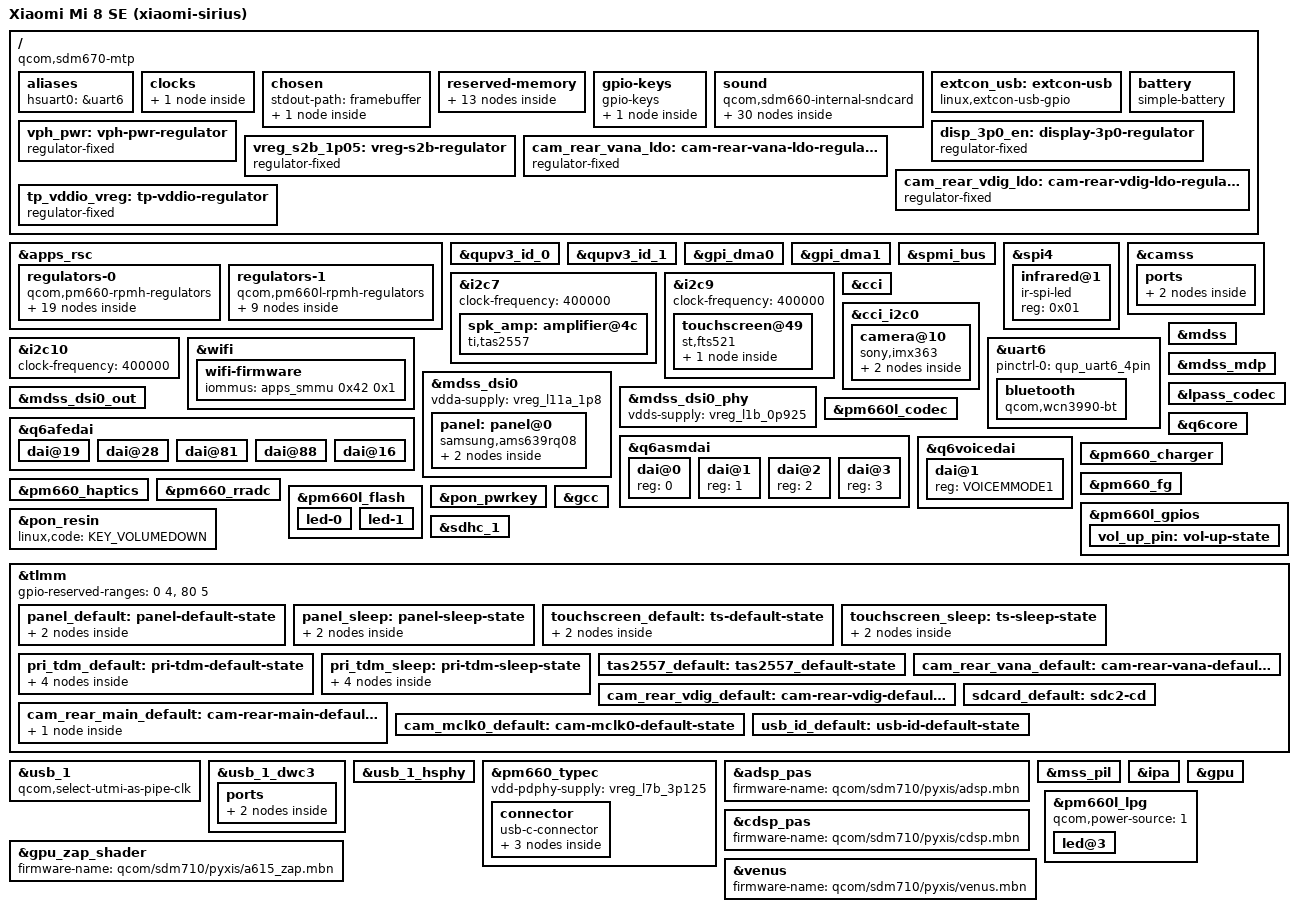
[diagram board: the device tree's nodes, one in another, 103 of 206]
// SPDX-License-Identifier: GPL-2.0
/*
 * Device tree for Xiaomi Mi 8 SE (xiaomi-sirius), based on
 * sdm670-google-sargo, downstream vendor kernel, and LineageOS DTS.
 *
 * Copyright (c) 2026, The Linux Foundation. All rights reserved.
*/

/dts-v1/;
#include <dt-bindings/firmware/qcom,scm.h>
#include <dt-bindings/gpio/gpio.h>
#include <dt-bindings/input/input.h>
#include <dt-bindings/leds/common.h>
#include <dt-bindings/pinctrl/qcom,pmic-gpio.h>
#include <dt-bindings/power/qcom-rpmpd.h>
#include <dt-bindings/sound/qcom,q6afe.h>
#include <dt-bindings/sound/qcom,q6asm.h>
#include <dt-bindings/sound/qcom,q6voice.h>
#include <dt-bindings/usb/pd.h>
#include "sdm710.dtsi"
#include "pm660.dtsi"
#include "pm660l.dtsi"

/delete-node/ &xbl_mem;
/delete-node/ &wlan_msa_mem;
/delete-node/ &cdsp_mem;
/delete-node/ &mba_region;
/delete-node/ &adsp_mem;
/delete-node/ &ipa_fw_mem;
/delete-node/ &ipa_gsi_mem;
/delete-node/ &gpu_mem;
/delete-node/ &rmtfs_mem;

/ {
	model = "Xiaomi Mi 8 SE (xiaomi-sirius)";
	compatible = "qcom,sdm670-mtp", "qcom,sdm670", "qcom,mtp";
	qcom,msm-id = <0x360 0 393 0>;
	qcom,board-id = <35 0>;
	chassis-type = "handset";

	aliases {
		hsuart0 = &uart6;
	};

	clocks {
		int_cdc_bclk: int-cdc-bclk {
			compatible = "fixed-clock";
			#clock-cells = <0>;
			clock-frequency = <1536000>;
		};
	};

	chosen {
		stdout-path = "framebuffer";
		#address-cells = <2>;
		#size-cells = <2>;
		ranges;

		framebuffer: framebuffer@9c000000 {
			compatible = "simple-framebuffer";
			reg = <0 0x9c000000 0 (1080 * 2240 * 4)>;
			width = <1080>;
			height = <2240>;
			stride = <(1080 * 4)>;
			format = "a8r8g8b8";
			status = "okay";
		};
	};

	reserved-memory {
		#address-cells = <2>;
		#size-cells = <2>;

		xbl_mem: memory@85e00000 {
			reg = <0 0x85e00000 0 0x1c0000>;
			no-map;
		};

		// 2026-10-15: old range 85fc0000-8ab00000 overlapped aop-mem + aop-cmd-db
		// (sdm670.dtsi, still no-map there) -> dmesg OVERLAP DETECTED. End kept 8ab00000.
		removed_region: removed-region {
			reg = <0 0x88f00000 0 0x1c00000>;
			no-map;
		};

		wlan_msa_mem: wlan-msa@93300000 {
			reg = <0 0x93300000 0 0x100000>;
			no-map;
		};

		cdsp_mem: cdsp@93400000 {
			reg = <0 0x93400000 0 0x800000>;
			no-map;
		};

		mba_region: mba@93c00000 {
			reg = <0 0x93c00000 0 0x200000>;
			no-map;
		};

		adsp_mem: adsp@93e00000 {
			reg = <0 0x93e00000 0 0x2200000>;
			no-map;
		};

		ipa_fw_mem: ipa-fw@97600000 {
			reg = <0 0x97600000 0 0x10000>;
			no-map;
		};

		ipa_gsi_mem: ipa-gsi@97610000 {
			reg = <0 0x97610000 0 0x5000>;
			no-map;
		};

		gpu_mem: gpu@97615000 {
			reg = <0 0x97615000 0 0x2000>;
			no-map;
		};

		fb_mem: framebuffer@9c000000 {
			reg = <0 0x9c000000 0 0x2300000>;
			no-map;
		};

		rmtfs_lower_guard: rmtfs-lower-guard@fc200000 {
			reg = <0 0xfc200000 0 0x1000>;
			no-map;
		};

		rmtfs_mem: rmtfs-mem@fc201000 {
			compatible = "qcom,rmtfs-mem";
			reg = <0 0xfc201000 0 0x200000>;
			no-map;
			qcom,client-id = <1>;
			qcom,vmid = <QCOM_SCM_VMID_MSS_MSA>;
		};

		rmtfs_upper_guard: rmtfs-upper-guard@fc401000 {
			reg = <0 0xfc401000 0 0x1000>;
			no-map;
		};
	};

	gpio-keys {
		compatible = "gpio-keys";
		autorepeat;

		pinctrl-names = "default";
		pinctrl-0 = <&vol_up_pin>;

		key-vol-up {
			label = "Volume Up";
			linux,code = <KEY_VOLUMEUP>;
			gpios = <&pm660l_gpios 7 GPIO_ACTIVE_LOW>;
		};
	};

	// AUDIO: WIP
	sound: sound {
		compatible = "qcom,sdm660-internal-sndcard";
		model = "Xiaomi Mi 8 SE";

		pinctrl-names = "default";
		/* cdc_pdm_default needs gpio18-20 (slimbus), taken by camera CCI on sirius; speaker/headset via TDM+tas2552 do not need it */
		pinctrl-0 = <&pri_tdm_default>;

		audio-routing = "Analog PDM_RX1", "Digital PDM_RX1",
			"Analog PDM_RX2", "Digital PDM_RX2",
			"Analog PDM_RX3", "Digital PDM_RX3",
			"Digital LPASS_PDM_TX", "Analog PDM_TX",
			"Analog AMIC1", "Analog MIC BIAS External1",
			"Analog AMIC2", "Analog MIC BIAS External2",
			"Analog AMIC3", "Analog MIC BIAS External1";

		mm1-dai-link {
			link-name = "MultiMedia1";

			cpu {
				sound-dai = <&q6asmdai MSM_FRONTEND_DAI_MULTIMEDIA1>;
			};
		};

		mm2-dai-link {
			link-name = "MultiMedia2";

			cpu {
				sound-dai = <&q6asmdai MSM_FRONTEND_DAI_MULTIMEDIA2>;
			};
		};

		mm3-dai-link {
			link-name = "MultiMedia3";

			cpu {
				sound-dai = <&q6asmdai MSM_FRONTEND_DAI_MULTIMEDIA3>;
			};
		};

		mm4-dai-link {
			link-name = "MultiMedia4";

			cpu {
				sound-dai = <&q6asmdai MSM_FRONTEND_DAI_MULTIMEDIA4>;
			};
		};

		voicemmode1-dai-link {
			link-name = "VoiceMMode1";

			cpu {
				sound-dai = <&q6voicedai VOICEMMODE1>;
			};
		};

		pri-tdm-tx-link {
			link-name = "Primary TDM0 Capture";

			cpu {
				sound-dai = <&q6afedai PRIMARY_TDM_TX_0>;
			};

			platform {
				sound-dai = <&q6routing>;
			};

			codec {
				sound-dai = <&spk_amp 0>;
			};
		};

		pri-mi2s-rx-link {
			link-name = "Primary MI2S Playback";

			cpu {
				sound-dai = <&q6afedai PRIMARY_MI2S_RX>;
			};

			platform {
				sound-dai = <&q6routing>;
			};

			codec {
				sound-dai = <&spk_amp 0>;
			};
		};

		sec-tdm-rx-link {
			link-name = "Secondary TDM0 Playback";

			cpu {
				sound-dai = <&q6afedai SECONDARY_TDM_RX_0>;
			};

			platform {
				sound-dai = <&q6routing>;
			};

			codec {
				sound-dai = <&spk_amp 0>;
			};
		};

		int0-mi2s-rx-link {
			link-name = "Internal MI2S Playback";

			cpu {
				sound-dai = <&q6afedai INT0_MI2S_RX>;
			};

			platform {
				sound-dai = <&q6routing>;
			};

			codec {
				sound-dai = <&pm660l_codec 0>, <&lpass_codec 0>;
			};
		};

		int3-mi2s-tx-link {
				link-name = "Internal MI2S Capture";

			cpu {
				sound-dai = <&q6afedai INT3_MI2S_TX>;
			};

			platform {
				sound-dai = <&q6routing>;
			};

			codec {
				sound-dai = <&pm660l_codec 1>, <&lpass_codec 1>;
			};
		};
};

	extcon_usb: extcon-usb {
		compatible = "linux,extcon-usb-gpio";
		id-gpios = <&tlmm 38 GPIO_ACTIVE_HIGH>;
		pinctrl-names = "default";
		pinctrl-0 = <&usb_id_default>;
	};

	battery: battery {
		compatible = "simple-battery";
		charge-full-design-microamp-hours = <3120000>;
		voltage-min-design-microvolt = <3312000>;
		voltage-max-design-microvolt = <4400000>;
	};

	/* Regulators */
	vph_pwr: vph-pwr-regulator {
		compatible = "regulator-fixed";
		regulator-name = "vph_pwr";
		regulator-min-microvolt = <3312000>;
		regulator-max-microvolt = <3312000>;
		regulator-always-on;
		regulator-boot-on;
	};

	disp_3p0_en: display-3p0-regulator {
		compatible = "regulator-fixed";
		regulator-name = "disp_3p0_en";
		gpios = <&tlmm 76 GPIO_ACTIVE_HIGH>;
		enable-active-high;
		regulator-boot-on;
	};

	vreg_s2b_1p05: vreg-s2b-regulator {
		compatible = "regulator-fixed";
		regulator-name = "vreg_s2b";
		regulator-min-microvolt = <1050000>;
		regulator-max-microvolt = <1050000>;
	};

	/* Camera: rear main Sony IMX363 (12MP) */
	/* VANA 2.8V, enable via GPIO 8, input PM660L BOB */
	cam_rear_vana_ldo: cam-rear-vana-ldo-regulator {
		compatible = "regulator-fixed";
		regulator-name = "cam_rear_vana_ldo";
		regulator-min-microvolt = <2800000>;
		regulator-max-microvolt = <2800000>;
		regulator-enable-ramp-delay = <233>;

		gpios = <&tlmm 8 GPIO_ACTIVE_HIGH>;
		enable-active-high;
		vin-supply = <&vreg_bob>;

		pinctrl-0 = <&cam_rear_vana_default>;
		pinctrl-names = "default";
	};

	/* VDIG 1.35V, enable via GPIO 29, input PM660 S6 */
	cam_rear_vdig_ldo: cam-rear-vdig-ldo-regulator {
		compatible = "regulator-fixed";
		regulator-name = "cam_rear_vdig_ldo";
		regulator-min-microvolt = <1350000>;
		regulator-max-microvolt = <1350000>;
		regulator-enable-ramp-delay = <233>;

		gpios = <&tlmm 29 GPIO_ACTIVE_HIGH>;
		enable-active-high;
		vin-supply = <&vreg_s6a_0p87>;

		pinctrl-0 = <&cam_rear_vdig_default>;
		pinctrl-names = "default";
	};

	tp_vddio_vreg: tp-vddio-regulator {
		compatible = "regulator-fixed";
		regulator-name = "tp_vddio_vreg";
		regulator-enable-ramp-delay = <4000>;
		enable-active-high;
		regulator-boot-on;
		gpio = <&tlmm 26 GPIO_ACTIVE_HIGH>;
	};
};

/* Regulators */
&apps_rsc {
	regulators-0 {
		compatible = "qcom,pm660-rpmh-regulators";
		qcom,pmic-id = "a";

		vdd-s1-supply = <&vph_pwr>;
		vdd-s2-supply = <&vph_pwr>;
		vdd-s3-supply = <&vph_pwr>;
		vdd-s4-supply = <&vph_pwr>;
		vdd-s5-supply = <&vph_pwr>;
		vdd-s6-supply = <&vph_pwr>;

		vdd-l1-l6-l7-supply = <&vreg_s6a_0p87>;
		vdd-l2-l3-supply = <&vreg_s2b_1p05>;
		vdd-l5-supply = <&vreg_s2b_1p05>;
		vdd-l8-l9-l10-l11-l12-l13-l14-supply = <&vreg_s4a_2p04>;
		vdd-l15-l16-l17-l18-l19-supply = <&vreg_bob>;

		/*
		 * S1A (FTAPC0), S2A (FTAPC1), S3A (HFAPC1) are managed
		 * by the Core Power Reduction hardened (CPRh) and the
		 * Operating State Manager (OSM) HW automatically.
		 */

		vreg_s4a_2p04: smps4 {
			regulator-min-microvolt = <1808000>;
			regulator-max-microvolt = <2040000>;
			regulator-enable-ramp-delay = <200>;
		};

		vreg_s6a_0p87: smps6 {
			regulator-min-microvolt = <1224000>;
			regulator-max-microvolt = <1352000>;
			regulator-enable-ramp-delay = <150>;
		};

		/* LDOs */
		vreg_l1a_1p225: ldo1 {
			regulator-min-microvolt = <1200000>;
			regulator-max-microvolt = <1250000>;
			regulator-enable-ramp-delay = <250>;
		};

		vreg_l2a_1p0: ldo2 {
			regulator-min-microvolt = <1000000>;
			regulator-max-microvolt = <1000000>;
			regulator-enable-ramp-delay = <250>;
		};

		vreg_l3a_1p0: ldo3 {
			regulator-min-microvolt = <1000000>;
			regulator-max-microvolt = <1000000>;
			regulator-enable-ramp-delay = <250>;
		};

		// Possibly unused according to stock (dumped) DT...
		vreg_l5a_0p848: ldo5 {
			regulator-min-microvolt = <800000>;
			regulator-max-microvolt = <800000>;
			regulator-enable-ramp-delay = <250>;
		};

		vreg_l6a_1p3: ldo6 {
			regulator-min-microvolt = <1248000>;
			regulator-max-microvolt = <1304000>;
			regulator-enable-ramp-delay = <250>;
		};

		vreg_l7a_1p2: ldo7 {
			regulator-min-microvolt = <1200000>;
			regulator-max-microvolt = <1200000>;
			regulator-enable-ramp-delay = <250>;
		};

		vreg_l8a_1p8: ldo8 {
			regulator-min-microvolt = <1800000>;
			regulator-max-microvolt = <1800000>;
			regulator-enable-ramp-delay = <250>;
			regulator-always-on;
		};

		vreg_l9a_1p8: ldo9 {
			regulator-min-microvolt = <1800000>;
			regulator-max-microvolt = <1800000>;
			regulator-enable-ramp-delay = <250>;
		};

		vreg_l10a_1p8: ldo10 {
			regulator-min-microvolt = <1800000>;
			regulator-max-microvolt = <1800000>;
			regulator-enable-ramp-delay = <250>;
		};

		vreg_l11a_1p8: ldo11 {
			regulator-min-microvolt = <1800000>;
			regulator-max-microvolt = <1800000>;
			regulator-enable-ramp-delay = <250>;
		};

		vreg_l12a_1p8: ldo12 {
			regulator-min-microvolt = <1800000>;
			regulator-max-microvolt = <1800000>;
			regulator-enable-ramp-delay = <250>;
		};

		vreg_l13a_1p8: ldo13 {
			regulator-min-microvolt = <1800000>;
			regulator-max-microvolt = <1800000>;
			regulator-enable-ramp-delay = <250>;
		};

		vreg_l14a_1p8: ldo14 {
			regulator-min-microvolt = <1800000>;
			regulator-max-microvolt = <1800000>;
			regulator-enable-ramp-delay = <250>;
		};

		vreg_l15a_1p8: ldo15 {
			regulator-min-microvolt = <1800000>;
			regulator-max-microvolt = <2950000>;
			regulator-enable-ramp-delay = <250>;
		};

		// Stock sets it to 2700000, but range seems unsupported...
		vreg_l16a_2p7: ldo16 {
			regulator-min-microvolt = <2696000>;
			regulator-max-microvolt = <2696000>;
			regulator-enable-ramp-delay = <250>;
		};

		vreg_l17a_1p8: ldo17 {
			regulator-min-microvolt = <1800000>;
			regulator-max-microvolt = <2950000>;
			regulator-enable-ramp-delay = <250>;
		};

		vreg_l19a_3p3: ldo19 {
			regulator-min-microvolt = <3000000>;
			regulator-max-microvolt = <3312000>;
			regulator-enable-ramp-delay = <250>;
		};
	};

	regulators-1 {
		compatible = "qcom,pm660l-rpmh-regulators";
		qcom,pmic-id = "b";

		vdd-s1-supply = <&vph_pwr>;
		vdd-s2-supply = <&vph_pwr>;
		vdd-s3-s4-supply = <&vph_pwr>;
		vdd-s5-supply = <&vph_pwr>;

		vdd-l1-l9-l10-supply = <&vreg_s2b_1p05>;
		vdd-l2-supply = <&vreg_bob>;
		vdd-l3-l5-l7-l8-supply = <&vreg_bob>;
		vdd-l4-l6-supply = <&vreg_bob>;
		vdd-bob-supply = <&vph_pwr>;

		/* LDOs */
		vreg_l1b_0p925: ldo1 {
			regulator-min-microvolt = <880000>;
			regulator-max-microvolt = <900000>;
			regulator-enable-ramp-delay = <250>;
		};

		vreg_l2b_2p95: ldo2 {
			regulator-min-microvolt = <1800000>;
			regulator-max-microvolt = <2960000>;
			regulator-enable-ramp-delay = <250>;
		};

		vreg_l3b_3p0: ldo3 {
			regulator-min-microvolt = <2800000>;
			regulator-max-microvolt = <3008000>;
			regulator-enable-ramp-delay = <250>;
		};

		vreg_l4b_2p95: ldo4 {
			regulator-min-microvolt = <2960000>;
			regulator-max-microvolt = <2960000>;
			regulator-enable-ramp-delay = <250>;
		};

		vreg_l5b_1p8: ldo5 {
			regulator-min-microvolt = <1800000>;
			regulator-max-microvolt = <1800000>;
			regulator-enable-ramp-delay = <250>;
		};

		vreg_l6b_3p3: ldo6 {
			regulator-min-microvolt = <3008000>;
			regulator-max-microvolt = <3300000>;
			regulator-enable-ramp-delay = <250>;
		};

		vreg_l7b_3p125: ldo7 {
			regulator-min-microvolt = <3088000>;
			regulator-max-microvolt = <3100000>;
			regulator-enable-ramp-delay = <250>;
		};

		vreg_l8b_3p3: ldo8 {
			regulator-min-microvolt = <3300000>;
			regulator-max-microvolt = <3312000>;
			regulator-enable-ramp-delay = <250>;
		};

		/*
		 * Downstream specifies a fixed voltage of 3.312 V, but the
		 * PMIC4 BOB ranges don't support that. Widen the range a
		 * little to avoid adding a new BOB regulator type.
		 */
		vreg_bob: bob {
			regulator-min-microvolt = <3296000>;
			regulator-max-microvolt = <3328000>;
			regulator-enable-ramp-delay = <500>;
		};
	};
};

/* Enable i2c/spi blocks */
&qupv3_id_0 {
	status = "okay";
};

&qupv3_id_1 {
	status = "okay";
};

&gpi_dma0 {
	status = "okay";
};

&gpi_dma1 {
	status = "okay";
};

&spmi_bus {
	status = "okay";
};

/* IR blaster */
&spi4 {
	status = "okay";

	infrared@1 {
		compatible = "ir-spi-led";
		reg = <0x01>;
	};
};

/* Audio amp */
&i2c7 {
	status = "okay";
	clock-frequency = <400000>;

	spk_amp: amplifier@4c {
		compatible = "ti,tas2557";
		reg = <0x4c>;
		#sound-dai-cells = <1>;

		ti,cdc-reset-gpio = <&tlmm 95 GPIO_ACTIVE_HIGH>;
		ti,irq-gpio = <&tlmm 96 0>;

		vbat-supply = <&vph_pwr>;
		iovdd-supply = <&vreg_l13a_1p8>;
		avdd-supply = <&vreg_l13a_1p8>;
	};
};



	/* Touchscreen */
	&i2c9 {
		status = "okay";
		clock-frequency = <400000>;

		touchscreen@49 {
			compatible = "st,fts521";
			reg = <0x49>;

			interrupts-extended = <&tlmm 125 IRQ_TYPE_LEVEL_LOW>;

			pinctrl-names = "pmx_ts_active", "pmx_ts_suspend";
			pinctrl-0 = <&touchscreen_default>;
			pinctrl-1 = <&touchscreen_sleep>;

			avdd-supply = <&vreg_l6b_3p3>;
			vdd-supply = <&tp_vddio_vreg>;
			fts,pwr-reg-name = "avdd";
			fts,bus-reg-name = "vdd";

			touchscreen-size-x = <1080>;
			touchscreen-size-y = <2244>;

			fts,irq-gpio = <&tlmm 125 0x00>;
			fts,reset-gpio-enable;
			fts,reset-gpio = <&tlmm 99 0x00>;
			fts,irq-flags = <0x2008>;
			fts,key-num = <2>;
			fts,key-codes = <158 139>;
			fts,x-max = <1080>;
			fts,y-max = <2244>;
			fts,config-array-size = <1>;
			fts,cfg_0 {
				fts,tp-vendor = <0x48>;
				fts,fw-name = "st_fts_v521.ftb";
				fts,limit-name = "stm_fts_production_limits.csv";
			};
		};
	};
&i2c10 {
	status = "okay";
	clock-frequency = <400000>;

	// smb1355@8
	// smb1355@c
};

/* Camera: the rear main sensor is a Sony IMX363 (12MP, 1/2.55").
 * CSI_0, CCI master 0, CAM_W_MCLK0 (GPIO 13), CAM_RESET0 (GPIO 30).
 * The front (S5K3T1, CSI_2) and rear depth (S5K5E8, CSI_1) sensors
 * have no mainline driver yet, so they are not described here. */

/* Camera subsystem */
&camss {
	vdda-phy-supply = <&vreg_l1a_1p225>;
	vdda-pll-supply = <&vreg_s6a_0p87>;
	status = "okay";

	ports {
		port@0 {
			camss_endpoint0: endpoint {
				clock-lanes = <7>;
				data-lanes = <0 1 2 3>;
				remote-endpoint = <&cam_rear_main_endpoint>;
			};
		};
	};
};

&cci {
	pinctrl-names = "default", "sleep";
	pinctrl-0 = <&cci0_default &cci1_default &cam_mclk0_default>;
	pinctrl-1 = <&cci0_sleep &cci1_sleep>;

	status = "okay";
};

&cci_i2c0 {
	camera@10 {
		compatible = "sony,imx363";
		reg = <0x10>;

		clocks = <&camcc CAM_CC_MCLK0_CLK>;
		clock-names = "xvclk";
		clock-frequency = <24000000>;
		assigned-clocks = <&camcc CAM_CC_MCLK0_CLK>;
		assigned-clock-rates = <24000000>;

		reset-gpios = <&tlmm 30 GPIO_ACTIVE_LOW>;

		/* Rear sensor needs a 270 degree clockwise correction to match
		 * the phone's natural (portrait) orientation. */
		rotation = <270>;
		orientation = <1>; /* back */

		vif-supply = <&vreg_l14a_1p8>;
		vana-supply = <&cam_rear_vana_ldo>;
		vdig-supply = <&cam_rear_vdig_ldo>;

		pinctrl-names = "default";
		pinctrl-0 = <&cam_rear_main_default>;

		port {
			cam_rear_main_endpoint: endpoint {
				data-lanes = <0 1 2 3>;
				link-frequencies = /bits/ 64 <321000000 636000000>;
				remote-endpoint = <&camss_endpoint0>;
			};
		};
	};
};

/* WiFi and Bluetooth */
&wifi {
	status = "okay";

	vdd-0.8-cx-mx-supply = <&vreg_l5a_0p848>;
	vdd-1.8-xo-supply = <&vreg_l9a_1p8>;
	vdd-1.3-rfa-supply = <&vreg_l6a_1p3>;
	vdd-3.3-ch0-supply = <&vreg_l19a_3p3>;
	vdd-3.3-ch1-supply = <&vreg_l19a_3p3>;

	qcom,snoc-host-cap-8bit-quirk;
	qcom,ath10k-calibration-variant = "xiaomi_sirius";

	wifi-firmware {
		iommus = <&apps_smmu 0x42 0x1>;
	};
};

&uart6 {
	pinctrl-0 = <&qup_uart6_4pin>;
	status = "okay";

	bluetooth {
		compatible = "qcom,wcn3990-bt";
		vddio-supply = <&vph_pwr>;
		vddxo-supply = <&vreg_l9a_1p8>;
		vddrf-supply = <&vreg_l6a_1p3>;
		vddch0-supply = <&vreg_l19a_3p3>;
		max-speed = <3200000>;
	};
};

/* Display Subsystem */
&mdss {
	status = "okay";
};

&mdss_dsi0 {
	status = "okay";
	vdda-supply = <&vreg_l11a_1p8>;

	panel: panel@0 {
		status = "okay";
		compatible = "samsung,ams639rq08";
		reg = <0>;

		te-gpios = <&tlmm 10 GPIO_ACTIVE_LOW>;
		reset-gpios = <&tlmm 75 GPIO_ACTIVE_LOW>;

		pinctrl-names = "default", "sleep";
		pinctrl-0 = <&panel_default>;
		pinctrl-1 = <&panel_sleep>;

		vddio-supply = <&disp_3p0_en>;
		vdd3p3-supply = <&vreg_l8b_3p3>;

		port {
			panel_in: endpoint {
				remote-endpoint = <&mdss_dsi0_out>;
			};
		};
	};
};

&mdss_dsi0_out {
	data-lanes = <0 1 2 3>;
	remote-endpoint = <&panel_in>;
};

&mdss_dsi0_phy {
	status = "okay";
	vdds-supply = <&vreg_l1b_0p925>;
};

&mdss_mdp {
	status = "okay";
};

/* Audio - WIP */
&pm660l_codec {
	vdd-cdc-io-supply = <&vreg_l13a_1p8>;
	vdd-cdc-tx-rx-cx-supply = <&vreg_l1b_0p925>;
	vdd-micbias-supply = <&vreg_l3b_3p0>;

	qcom,mbhc-vthreshold-low = <75 150 237 437 437>;
	qcom,mbhc-vthreshold-high = <75 150 237 437 437>;

	status = "okay";
};

&lpass_codec {
	clocks = <&q6afecc LPASS_CLK_ID_INT_MCLK_0 LPASS_CLK_ATTRIBUTE_COUPLE_NO>,
	         <&int_cdc_bclk>;
	clock-names = "mclk", "ahbix-clk";

	assigned-clocks = <&q6afecc LPASS_CLK_ID_INT_MCLK_0 LPASS_CLK_ATTRIBUTE_COUPLE_NO>;
	assigned-clock-rates = <9600000>;

	status = "okay";
};

/*
 * LPI TLMM must stay disabled: APPS access to the LPASS LPI block hangs
 * sirius even with the q6afecc macro/dcodec vote clocks and an active
 * ADSP audio stream (verified three times).  The PM660L PDM mic pins
 * therefore cannot be muxed from Linux with the mainline LPI driver.
 */
//&lpi_tlmm {
//	status = "okay";
//
//	clocks = <&q6afecc LPASS_HW_MACRO_VOTE LPASS_CLK_ATTRIBUTE_COUPLE_NO>,
//		 <&q6afecc LPASS_HW_DCODEC_VOTE LPASS_CLK_ATTRIBUTE_COUPLE_NO>;
//	clock-names = "core", "audio";
//};

&q6afedai {
	dai@19 {
		reg = <PRIMARY_TDM_TX_0>;

		qcom,tdm-sync-mode = <0>;
		qcom,tdm-sync-src = <1>;
		qcom,tdm-data-out = <0>;
		qcom,tdm-invert-sync = <0>;
		qcom,tdm-data-delay = <1>;
		qcom,tdm-data-align = <0>;
	};

	dai@28 {
		reg = <SECONDARY_TDM_RX_0>;

		qcom,tdm-sync-mode = <0>;
		qcom,tdm-sync-src = <1>;
		qcom,tdm-data-out = <0>;
		qcom,tdm-invert-sync = <0>;
		qcom,tdm-data-delay = <1>;
		qcom,tdm-data-align = <0>;
	};

	dai@81 {
		reg = <INT0_MI2S_RX>;
		qcom,sd-lines = <0 1>;
	};

	dai@88 {
		reg = <INT3_MI2S_TX>;
		qcom,sd-lines = <0 1>;
	};
};

&q6asmdai {
	dai@0 {
		reg = <0>;
	};

	dai@1 {
		reg = <1>;
	};

	dai@2 {
		reg = <2>;
	};

	dai@3 {
		reg = <3>;
	};
};

&q6core {
		qcom,acdb-name = "qcom/sdm710/pyxis/Global_cal.acdb";
};

&q6voicedai {
	dai@1 {
		reg = <VOICEMMODE1>;
	};
};

/* PMIC */
&pm660_charger {
	monitored-battery = <&battery>;
	/* TCPM owns the USB input current limit (PD contract / Rp) */
	qcom,typec-managed-icl;
	/* ... and the OTG boost bit, driven through tcpc->set_vbus() */
	qcom,typec-managed-vbus;
	status = "okay";
};

&pm660_fg {
	monitored-battery = <&battery>;
	power-supplies = <&pm660_charger>;
	status = "okay";
};

&pm660_haptics {
	status = "okay";
	// Motor needs 3.2V 800mA.
	// HAP_ILIM_800_MA should be set.
};

&pm660_rradc {
	status = "okay";
};

&pm660l_flash {
	status = "okay";

	led-0 {
		function = LED_FUNCTION_FLASH;
		color = <LED_COLOR_ID_WHITE>;
		led-sources = <1>, <2>;
		led-max-microamp = <350000>;
		flash-max-microamp = <1000000>;
		flash-max-timeout-us = <1280000>;
	};
};

&pm660l_gpios {
	vol_up_pin: vol-up-state {
		pins = "gpio7";
		function = "normal";
		qcom,drive-strength = <PMIC_GPIO_STRENGTH_NO>;
		input-enable;
		bias-pull-up;
	};
};

&pon_pwrkey {
	status = "okay";
};

&pon_resin {
	linux,code = <KEY_VOLUMEDOWN>;
	status = "okay";
};

/* Storage: eMMC */
&sdhc_1 {
	status = "okay";

	vmmc-supply = <&vreg_l8b_3p3>;
	vqmmc-supply = <&vreg_l5b_1p8>;

	bus-width = <8>;
	non-removable;

	mmc-hs400-1_8v;
};

/* Global Clock Controller */
&gcc {
	protected-clocks = <GCC_QSPI_CORE_CLK>,
		<GCC_QSPI_CORE_CLK_SRC>,
		<GCC_QSPI_CNOC_PERIPH_AHB_CLK>;
};

/* SoC GPIO aka pinctrl */
&tlmm {
	gpio-reserved-ranges = <0 4>, <80 5>;

	/* GPIOs for display panel */
	panel_default: panel-default-state {
		te-pins {
			pins = "gpio10";
			function = "mdp_vsync";
			drive-strength = <2>;
			bias-pull-down;
		};

		reset-pins {
			pins = "gpio75";
			function = "gpio";
			drive-strength = <8>;
			bias-disable;
		};
	};

	panel_sleep: panel-sleep-state {
		te-pins {
			pins = "gpio10";
			function = "mdp_vsync";
			drive-strength = <2>;
			bias-pull-down;
		};

		reset-pins {
			pins = "gpio75";
			function = "gpio";
			drive-strength = <8>;
			bias-disable;
		};
	};

	/* GPIOs for touchscreen */
		touchscreen_default: ts-default-state {
		ts-irq-pins {
			pins = "gpio125";
			function = "gpio";
			drive-strength = <16>;
			bias-pull-up;
		};

		ts-reset-pins {
			pins = "gpio99";
			function = "gpio";
			drive-strength = <16>;
			bias-pull-up;
		};
	};

	touchscreen_sleep: ts-sleep-state {
		ts-irq-pins {
			pins = "gpio125";
			function = "gpio";
			drive-strength = <2>;
			bias-disable;
			input-enable;
		};

		ts-reset-pins {
			pins = "gpio99";
			function = "gpio";
			drive-strength = <2>;
			bias-disable;
			input-enable;
		};
	};
	pri_tdm_default: pri-tdm-default-state {
		misc-pins {
			pins = "gpio65";
			function = "pri_mi2s";
			drive-strength = <8>;
		};

		ws-pins {
			pins = "gpio66";
			function = "pri_mi2s_ws";
			drive-strength = <8>;
		};

		dout-pins {
			pins = "gpio67";
			function = "pri_mi2s";
			drive-strength = <8>;
		};

		din-pins {
			pins = "gpio68";
			function = "pri_mi2s";
			drive-strength = <8>;
		};
	};

	pri_tdm_sleep: pri-tdm-sleep-state {
		misc-pins {
			pins = "gpio65";
			function = "pri_mi2s";
			drive-strength = <2>;
			bias-pull-down;
		};

		ws-pins {
			pins = "gpio66";
			function = "pri_mi2s_ws";
			drive-strength = <2>;
			bias-pull-down;
		};

		dout-pins {
			pins = "gpio67";
			function = "pri_mi2s";
			drive-strength = <2>;
			bias-pull-down;
		};

		din-pins {
			pins = "gpio68";
			function = "pri_mi2s";
			drive-strength = <2>;
			bias-pull-down;
		};
	};

	/* GPIOs for Speaker Amplifier */
	tas2557_default: tas2557_default-state {
		pins = "gpio95", "gpio96";
		function = "gpio";
		drive-strength = <2>;
	};

	/* Camera power enables and reset (rear main IMX363) */
	cam_rear_vana_default: cam-rear-vana-default-state {
		pins = "gpio8";
		function = "gpio";
		drive-strength = <2>;
		bias-disable;
	};

	cam_rear_vdig_default: cam-rear-vdig-default-state {
		pins = "gpio29";
		function = "gpio";
		drive-strength = <2>;
		bias-disable;
	};

	cam_rear_main_default: cam-rear-main-default-state {
		reset-pins {
			pins = "gpio30";
			function = "gpio";
			drive-strength = <2>;
			bias-disable;
		};
	};

	/* Camera MCLK0 (GPIO 13) */
	cam_mclk0_default: cam-mclk0-default-state {
		pins = "gpio13";
		function = "cam_mclk";
		drive-strength = <2>;
		bias-disable;
	};

	/* MicroSD card-detect */
	sdcard_default: sdc2-cd {
		pins = "gpio126";
		function = "gpio";
		drive-strength = <2>;
		bias-pull-up;
	};

	/* USB ID pin for OTG detection via extcon-usb-gpio */
	usb_id_default: usb-id-default-state {
		pins = "gpio38";
		function = "gpio";
		drive-strength = <2>;
		bias-pull-up;
	};
};

/* USB: Only USB2.0 because Xiaomi are cheapskates */
&usb_1 {
	status = "okay";
	qcom,select-utmi-as-pipe-clk;
};

&usb_1_dwc3 {
	dr_mode = "otg";
	/*
	 * Role is driven by the Type-C port (PM660 Type-C block + TCPM)
	 * through the USB role switch; the legacy ID-pin extcon is no
	 * longer used for the role decision.
	 */
	usb-role-switch;
	role-switch-default-mode = "peripheral";
	phys = <&usb_1_hsphy>;
	phy-names = "usb2-phy";
	maximum-speed = "high-speed";

	/delete-property/ snps,dis_u2_susphy_quirk;
	/delete-property/ snps,dis_enblslpm_quirk;

	ports {
		#address-cells = <1>;
		#size-cells = <0>;

		port@0 {
			reg = <0>;

			usb_1_dwc3_hs_out: endpoint {
			};
		};
	};
};

&usb_1_hsphy {
	status = "okay";
	vdd-supply = <&vreg_l1b_0p925>;
	vdda-pll-supply = <&vreg_l10a_1p8>;
	vdda-phy-dpdm-supply = <&vreg_l7b_3p125>;

	/*
	 * Tuning values from downstream qusb-phy-init-seq, overriding the
	 * qusb2-v2 init table defaults where they differ:
	 *   IMP_CTRL1:   0x08 → imp-res-offset = 8
	 *   TUNE1:       0x07 → hstx-trim = 0 (24.0 mA),
	 *                         preemphasis = 3 (15%),
	 *                         preemphasis-width = 1 (half-bit)
	 *   TUNE2:       0x29 → hsdisc-trim = 1 (matches mainline default)
	 */
	qcom,imp-res-offset-value = <8>;
	qcom,hstx-trim-value = <0>;		/* 24.0 mA */
	qcom,preemphasis-level = <3>;		/* 15% */
	qcom,preemphasis-width = <1>;		/* half-bit */
};

/*
 * Type-C: the PM660 charger's CC state machine is driven by the generic
 * Type-C Port Controller Manager, which also owns the role switch and the
 * PD PHY.  Sink capabilities mirror the vendor "default-sink-caps" table.
 */
&pm660_typec {
	status = "okay";

	vdd-pdphy-supply = <&vreg_l7b_3p125>;

	connector {
		compatible = "usb-c-connector";
		label = "USB-C";
		power-role = "dual";
		data-role = "dual";
		try-power-role = "sink";

		/*
		 * A DRP port must advertise both directions; TCPM refuses to
		 * register otherwise.  5 V/1.5 A matches what the SMB2 boost
		 * can reasonably deliver through a plain OTG adapter.
		 */
		source-pdos = <PDO_FIXED(5000, 1500,
					 PDO_FIXED_DUAL_ROLE |
					 PDO_FIXED_USB_COMM |
					 PDO_FIXED_DATA_SWAP)>;
		sink-pdos = <PDO_FIXED(5000, 3000,
				       PDO_FIXED_DUAL_ROLE |
				       PDO_FIXED_USB_COMM)
			     PDO_FIXED(9000, 2000,
				       PDO_FIXED_DUAL_ROLE |
				       PDO_FIXED_USB_COMM)>;
		op-sink-microwatt = <15000000>;

		ports {
			#address-cells = <1>;
			#size-cells = <0>;

			port@0 {
				reg = <0>;

				pm660_typec_hs: endpoint {
					remote-endpoint = <&usb_1_dwc3_hs_out>;
				};
			};
		};
	};
};

/* Remote-USB-ID extcon is kept for userspace compatibility only */
/* Remoteproc etc. */
&adsp_pas {
	status = "okay";
	firmware-name = "qcom/sdm710/pyxis/adsp.mbn";
};

&cdsp_pas {
	status = "okay";
	firmware-name = "qcom/sdm710/pyxis/cdsp.mbn";
};

&mss_pil {
	status = "okay";
	firmware-name = "qcom/sdm710/pyxis/mba.mbn",
			"qcom/sdm710/pyxis/modem.mbn";
};

&ipa {
	status = "okay";
	qcom,gsi-loader = "self";
	memory-region = <&ipa_fw_mem>;
	firmware-name = "qcom/sdm710/pyxis/ipa_fws.mbn";
};

&gpu {
	status = "okay";
};

&gpu_zap_shader {
	firmware-name = "qcom/sdm710/pyxis/a615_zap.mbn";
};

&venus {
	status = "okay";
	firmware-name = "qcom/sdm710/pyxis/venus.mbn";
};

/* PRI MI2S SD0 -> TAS2557 speaker amp (stock: SPEAKER on PRI_MI2S_RX) */
&q6afedai {
	dai@16 {
		reg = <PRIMARY_MI2S_RX>;
		qcom,sd-lines = <0>;
	};
};
/* Sirius LEDs, cf. downstream sirius-sdm710.dtsi +
 * sirius-sdm670-camera-sensor.dtsi:
 *  - rear dual flash  = PM660L flash strings 1+2 (ganged as led-0)
 *  - front fill light = PM660L flash string 3 (downstream flash2/torch2)
 *  - notification     = PM660L LPG channel 3 (downstream red_led/"white")
 */
&pm660l_flash {
	/* Front fill light (single string, downstream pm660l_flash2) */
	led-1 {
		function = LED_FUNCTION_FLASH;
		color = <LED_COLOR_ID_WHITE>;
		function-enumerator = <1>;
		led-sources = <3>;
		led-max-microamp = <100000>;
		flash-max-microamp = <1500000>;
		flash-max-timeout-us = <1280000>;
	};
};

&pm660l_lpg {
	#address-cells = <1>;
	#size-cells = <0>;
	qcom,power-source = <1>;
	status = "okay";

	/* Notification light: single white LED on LPG channel 3 */
	led@3 {
		reg = <3>;
		color = <LED_COLOR_ID_WHITE>;
		function = LED_FUNCTION_STATUS;
	};
};
